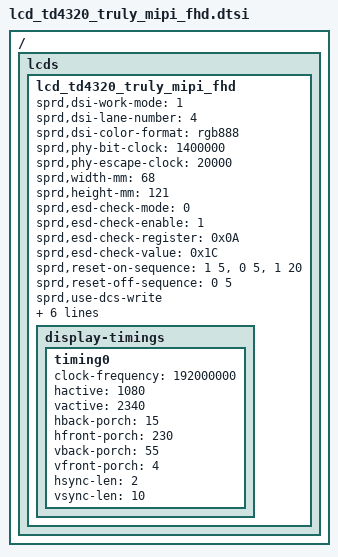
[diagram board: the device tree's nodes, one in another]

/*
 * TD4320  LCD config dtsi file for spreadtrum
 *
 * Copyright (C) 2018, Spreadtrum Communications Inc.
 *
 * SPDX-License-Identifier: (GPL-2.0+ OR MIT)
 */

/ {
	fragment {
		target-path = "/";
		__overlay__ {
			lcds {
				lcd_td4320_truly_mipi_fhd: lcd_td4320_truly_mipi_fhd {

					sprd,dsi-work-mode = <1>; /* video burst mode*/
					sprd,dsi-lane-number = <4>;
					sprd,dsi-color-format = "rgb888";

					sprd,phy-bit-clock = <1400000>;  /* kbps */
					sprd,phy-escape-clock = <20000>;/* kHz */

					sprd,width-mm = <68>;
					sprd,height-mm = <121>;

					sprd,esd-check-mode = <0>;
					sprd,esd-check-enable = <1>;
					sprd,esd-check-register = <0x0A>;
					sprd,esd-check-value = <0x1C>;

					sprd,reset-on-sequence = <1 5>, <0 5>, <1 20>;
					sprd,reset-off-sequence = <0 5>;

					sprd,use-dcs-write;
					sprd,initial-command = [
						29 00 00 02 B0 00
						29 00 00 06 B6 30 6b 00 82 03
						29 00 00 05 B7 51 00 00 00
						29 00 00 08 B8 57 3d 19 be 1e 0a 0a
						29 00 00 08 B9 6f 3d 28 be 3c 14 0a
						29 00 00 08 BA b5 33 41 be 64 23 0a
						29 00 00 0C BB 44 26 c3 1f 19 06 03 c0 00 00 10
						29 00 00 0C BC 32 4c c3 52 32 1f 03 f2 00 00 13
						29 00 00 0C BD 24 68 c3 aa 3f 32 03 ff 00 00 25
						29 00 00 0D BE 00 00 00 00 00 00 00 00 00 00 00 00
						29 00 00 0F C0 00 cb 01 2c 0c 09 24 00 46 00 00 08 00 00
						29 00 00 2A C1 30 00 00 11 00 00 00 00 22 00 05 20 00 80 fa 40 00 80 0f 00 00 00 00 00 00 00 00 00 00 00 00 00 00 00 00 00 00 00 00 00 00
						29 00 00 82 C2 00 a0 c0 02 02 00 09 05 00 00 00 00 00 00 00 00 00 00 00 00 00 00 00 00 00 00 00 00 a0 c0 04 04 01 01 c1 00 a0 0a 00 00 01 08 00 00 			      00 00 11 00 a0 0a 04 00 00 00 00 00 00 00 00 00 00 00 00 00 00 00 00 00 00 00 11 00 00 00 00 00 00 00 00 00 00 00 00 00 00 00 00 00 00 00 00 00 				 11 00 00 00 00 00 00 00 00 00 00 00 00 00 00 00 00 00 00 00 00 00 11 00 00 00 00 00 00 00 00 00 00 00 00 00 00
						29 00 00 6D C3 00 00 cb 01 93 b0 01 00 00 00 00 00 cb 01 00 09 9c 00 00 00 00 00 00 00 00 00 00 00 00 00 00 00 00 00 00 00 00 00 00 00 00 00 00 00 			      00 00 00 00 00 00 00 00 00 00 00 00 00 00 00 00 00 00 00 aa aa 00 00 00 00 00 00 01 00 01 00 00 00 00 00 c0 00 08 00 cb 00 00 01 00 00 c0 00 00 				 00 00 00 00 00 00 00 00 00 00 00 00 00 00 00 00
						29 00 00 62 C4 00 00 00 00 00 00 00 45 45 4c 51 4d 4d 61 5f 5d 0f 11 44 4f 4f be bf 03 00 00 00 00 00 00 00 45 45 4c 51 4d 4d 61 5f 5d 0e 10 44 4f 			      4f be bf 02 ff ff ff ff ff ff 80 fe e7 80 fe e7 00 02 18 00 02 18 00 e0 00 00 e0 00 00 00 00 00 00 00 04 04 00 00 04 04 00 00 00 00 00 50 00 00 				 00 00 00 00 00
						29 00 00 06 C5 08 00 00 00 00
						29 00 00 3F C6 02 1a 08 fc ff ff ff 00 00 13 01 ff 00 01 0c 3a 3a 3d 00 00 00 01 05 09 28 28 01 0c 3a 3a 3d 00 00 00 01 0b 00 00 00 1e 01 00 00 00 			      00 00 00 20 20 00 00 00 00 22 22 22 00 00 00 00 10 00
						29 00 00 0F CB a0 80 70 00 20 00 00 2d 41 00 00 00 00 ff
						29 00 00 22 CE 5d 40 49 53 59 5e 63 68 6e 74 7e 8a 98 a8 bb d0 e7 ff 04 00 04 04 42 00 69 5a 40 40 00 00 04 fa 00
						29 00 00 07 CF 00 00 80 a1 6a 00
						29 00 00 13 D0 c7 14 8a 66 09 90 00 cc 0f 05 c7 14 12 fe 09 09 cc 00
						29 00 00 1F D1 d3 d3 1b b0 07 07 3b 11 f1 11 f1 05 33 73 07 33 33 70 d3 d0 06 96 13 93 22 22 22 b3 bb 00
						29 00 00 12 D2 00 00 00 02 7f 00 00 00 00 00 00 00 00 00 00 00 00
						29 00 00 9A D3 00 00 00 00 00 00 00 00 00 ff f7 ff ff f7 ff ff f7 ff ff f7 ff ff f7 ff ff f7 ff ff f7 ff ff f7 ff ff f7 ff ff f7 ff ff f7 ff ff f7 			      ff ff f7 ff ff f7 ff ff f7 ff ff f7 ff ff f7 ff ff f7 ff ff f7 ff ff f7 ff ff f7 ff ff f7 ff ff f7 ff ff f7 ff ff f7 ff ff f7 ff ff f7 ff ff f7 				 ff ff f7 ff ff f7 ff ff f7 ff ff f7 ff ff f7 ff ff f7 ff ff f7 ff ff f7 ff ff f7 ff ff f7 ff ff f7 ff ff f7 ff ff f7 ff ff f7 ff ff f7 ff ff f7 			    ff ff f7 ff ff f7 ff ff f7 ff ff f7 ff
						29 00 00 18 D4 00 00 00 00 00 00 00 00 00 00 00 00 00 00 00 00 00 00 00 00 00 00 00
						29 00 00 4B D7 21 10 52 52 00 cb 00 46 00 b6 04 fd 01 00 03 00 05 05 05 07 04 05 06 07 00 02 02 08 03 03 08 04 08 08 0c 0b 0a 0a 0a 07 08 0a 06 00 			      08 00 00 00 00 00 04 04 04 04 04 04 04 02 04 04 04 04 04 04 04 04 04 04 06 06 00 00 00 00
						29 00 00 3F D8 00 12 00 00 00 00 00 00 00 00 00 00 00 00 00 00 00 00 00 00 00 00 00 00 00 00 00 00 00 00 00 00 00 00 00 00 00 00 00 00 00 00 00 00 			      00 00 00 00 00 00 00 00 00 00 00 00 00 00 00 00 00 00
						29 00 00 05 DD 30 06 23 65
						29 00 00 0B DE 00 00 00 0f ff 00 00 00 00 10
						29 00 00 05 E8 00 30 63 00
						29 00 00 1E EA 01 0e 02 c0 0a 40 a4 00 09 00 02 a6 00 00 00 00 00 00 00 00 04 c2 00 11 00 cb 0c b0 86
						29 00 00 08 EB 00 00 00 00 01 00 11
						29 00 00 0B EC 05 50 00 10 44 0a 40 a4 02 3a
						29 00 00 21 ED 01 01 02 02 08 08 09 09 00 00 00 00 02 00 00 00 00 12 02 c9 00 00 00 50 00 02 c9 00 00 a0 10 02
						29 00 00 61 EE c3 1f 00 00 00 fd 01 00 00 00 00 c2 5f 7f f0 03 00 00 00 00 00 00 00 c0 0f 7f 00 00 90 c9 09 09 c9 00 00 00 00 00 00 c0 01 00 00 00 			      00 c0 c0 00 00 00 00 0f 01 00 c3 1f 00 00 00 00 00 00 00 00 00 00 00 00 00 00 00 00 00 00 00 00 00 00 00 00 00 00 00 00 00 00 00 00 00 00 00 00 				 00 00 00 00
						29 00 00 67 EF 01 20 4c 08 60 00 00 00 00 32 32 32 00 00 00 00 00 00 00 00 00 00 00 00 00 00 00 01 20 4c 08 60 00 00 00 00 32 32 32 00 00 00 00 00 			      00 00 00 00 00 00 00 00 00 00 10 00 10 00 00 10 00 10 00 0a 0a 00 00 00 00 00 43 00 03 40 00 00 05 00 00 00 00 00 00 00 00 00 00 00 00 00 00 00 				 00 00 00 00 00 00 00 00 00 00
						29 00 00 06 F9 44 3f 00 8d bf
						29 00 00 02 B0 03
						29 00 00 02 B0 00
						29 00 00 05 E5 03 07 00 00
						29 00 00 4D C7 00 00 00 D4 01 4B 01 6F 01 86 01 8F 01 93 01 90 01 AB 01 79 01 C8 01 87 01 C9 01 7F 01 E3 01 D2 02 3C 02 9C 02 AE 00 00 00 D4 01 4B 			      01 6F 01 86 01 8F 01 93 01 90 01 AB 01 79 01 C8 01 87 01 C9 01 7F 01 E3 01 D2 02 3C 02 9C 02 AE
						29 00 00 02 51 FF
						29 00 00 02 53 0C
						29 00 00 02 55 00
						29 00 00 02 B0 03
						05 0a 00 01 29
						05 64 00 01 11
						];


					sprd,sleep-in-command = [
						13 0A 00 01 28
						13 78 00 01 10
						];
					sprd,sleep-out-command = [
						13 78 00 01 11
						13 32 00 01 29
						];

					display-timings {
						timing0 {
							clock-frequency = <192000000>;
							hactive = <1080>;
							vactive = <2340>;
							hback-porch = <15>;
							hfront-porch = <230>;
							vback-porch = <55>;
							vfront-porch = <4>;
							hsync-len = <2>;
							vsync-len = <10>;
						};
					};
				};
			};
		};
	};
};
